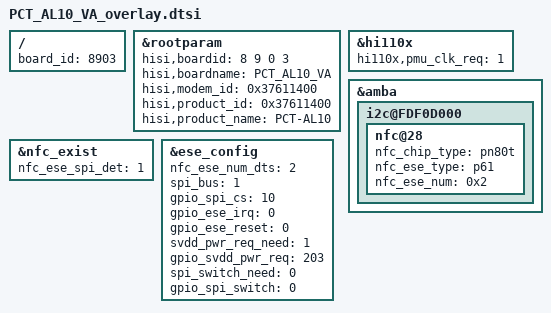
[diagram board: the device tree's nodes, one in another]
/**
 * Copyright (C) 2014 Hisilicon Ltd.
 *
 *  This program is free software; you can redistribute it and/or modify
 *  it under the terms of the GNU General Public License version 2 as
 *  publishhed by the Free Software Foundation.
 */

/include/ "PCT_TL00_VA_overlay.dtsi"

/ {
    board_id = <8903>;
};

	&rootparam{
		hisi,boardid = <8 9 0 3>;
		hisi,boardname = "PCT_AL10_VA";
		hisi,modem_id = <0x37611400>;
		hisi,product_id = <0x37611400>;
		hisi,product_name = "PCT-AL10";
	};

    /*hisi power*/
    &hi110x {
        hi110x,pmu_clk_req = <1>;
    };

	&amba {

		i2c@FDF0D000 {
			nfc@28{
				nfc_chip_type = "pn80t";
				nfc_ese_type = "p61";
				nfc_ese_num = <0x2>;
			};
		};
	};

	&nfc_exist {
		nfc_ese_spi_det = "1";
		status = "ok";
	};

	&ese_config {
		nfc_ese_num_dts = <2>;
		spi_bus = <1>;
		gpio_spi_cs = <10>;
		gpio_ese_irq = <0>;
		gpio_ese_reset = <0>;
		svdd_pwr_req_need = <1>;
		gpio_svdd_pwr_req = <203>;
		spi_switch_need = <0>;
		gpio_spi_switch = <0>;
		status = "ok";
	};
